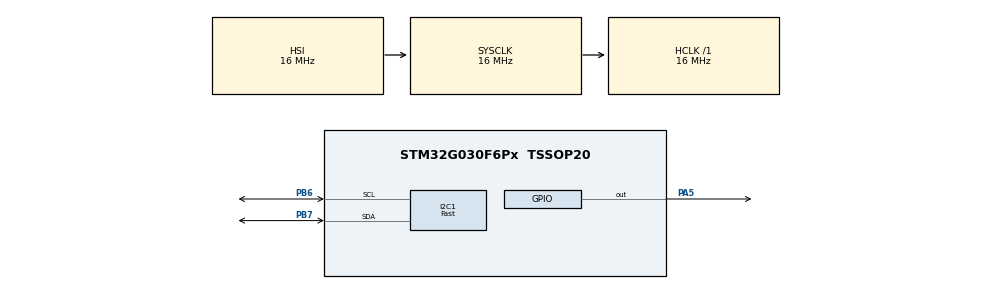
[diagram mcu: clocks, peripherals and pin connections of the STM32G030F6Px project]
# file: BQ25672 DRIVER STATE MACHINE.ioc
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Dma.I2C1_RX.0.Direction=DMA_PERIPH_TO_MEMORY
Dma.I2C1_RX.0.EventEnable=DISABLE
Dma.I2C1_RX.0.Instance=DMA1_Channel1
Dma.I2C1_RX.0.MemDataAlignment=DMA_MDATAALIGN_BYTE
Dma.I2C1_RX.0.MemInc=DMA_MINC_ENABLE
Dma.I2C1_RX.0.Mode=DMA_NORMAL
Dma.I2C1_RX.0.PeriphDataAlignment=DMA_PDATAALIGN_BYTE
Dma.I2C1_RX.0.PeriphInc=DMA_PINC_DISABLE
Dma.I2C1_RX.0.Polarity=HAL_DMAMUX_REQ_GEN_RISING
Dma.I2C1_RX.0.Priority=DMA_PRIORITY_LOW
Dma.I2C1_RX.0.RequestNumber=1
Dma.I2C1_RX.0.SignalID=NONE
Dma.I2C1_RX.0.SyncEnable=DISABLE
Dma.I2C1_RX.0.SyncPolarity=HAL_DMAMUX_SYNC_NO_EVENT
Dma.I2C1_RX.0.SyncRequestNumber=1
Dma.I2C1_RX.0.SyncSignalID=NONE
Dma.I2C1_TX.1.Direction=DMA_MEMORY_TO_PERIPH
Dma.I2C1_TX.1.EventEnable=DISABLE
Dma.I2C1_TX.1.Instance=DMA1_Channel2
Dma.I2C1_TX.1.MemDataAlignment=DMA_MDATAALIGN_BYTE
Dma.I2C1_TX.1.MemInc=DMA_MINC_ENABLE
Dma.I2C1_TX.1.Mode=DMA_NORMAL
Dma.I2C1_TX.1.PeriphDataAlignment=DMA_PDATAALIGN_BYTE
Dma.I2C1_TX.1.PeriphInc=DMA_PINC_DISABLE
Dma.I2C1_TX.1.Polarity=HAL_DMAMUX_REQ_GEN_RISING
Dma.I2C1_TX.1.Priority=DMA_PRIORITY_LOW
Dma.I2C1_TX.1.RequestNumber=1
Dma.I2C1_TX.1.SignalID=NONE
Dma.I2C1_TX.1.SyncEnable=DISABLE
Dma.I2C1_TX.1.SyncPolarity=HAL_DMAMUX_SYNC_NO_EVENT
Dma.I2C1_TX.1.SyncRequestNumber=1
Dma.I2C1_TX.1.SyncSignalID=NONE
Dma.Request0=I2C1_RX
Dma.Request1=I2C1_TX
I2C1.I2C_Speed_Mode=I2C_Fast
I2C1.Timing=0x00300617
Mcu.Family=STM32G0
Mcu.Name=STM32G030F6Px
Mcu.Package=TSSOP20
NVIC.DMA1_Channel1_IRQn=true\:0\:0\:false\:false\:true\:false\:true\:true
NVIC.DMA1_Channel2_3_IRQn=true\:0\:0\:false\:false\:true\:false\:true\:true
NVIC.TIM3_IRQn=true\:0\:0\:false\:false\:true\:true\:true\:true
PA14-BOOT0__PA15.StandardMode=true
PA5.Signal=GPIO_Output
PB0__PB1__PB2__PA8.StandardMode=true
PB3__PB4__PB5__PB6.StandardMode=true
PB6.Mode=I2C
PB6.Signal=I2C1_SCL
PB7.Mode=I2C
PB7.Signal=I2C1_SDA
PB7__PB8.StandardMode=true
PC14-OSC32_IN\ (PC14)__PB9.StandardMode=true
ProjectManager.HeapSize=0x200
ProjectManager.StackSize=0x400
ProjectManager.TargetToolchain=STM32CubeIDE
RCC.AHBFreq_Value=16000000
RCC.CortexFreq_Value=16000000
RCC.EXTERNAL_CLOCK_VALUE=12288000
RCC.HCLKFreq_Value=16000000
RCC.HSE_VALUE=8000000
RCC.HSI_VALUE=16000000
RCC.LSE_VALUE=32768
RCC.SYSCLKFreq_VALUE=16000000
RCC.VCOOutputFreq_Value=128000000
TIM3.AutoReloadPreload=TIM_AUTORELOAD_PRELOAD_ENABLE
TIM3.Period=99
TIM3.Prescaler=15999
VP_RTC_VS_RTC_Activate.Mode=RTC_Enabled
VP_TIM3_VS_ClockSourceINT.Mode=Internal
VP_TIM3_VS_ClockSourceITR.Mode=TriggerSource_ITR0
board=custom

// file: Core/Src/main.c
/* USER CODE BEGIN Header */
/**
  ******************************************************************************
  * @file           : main.c
  * @brief          : Main program body
  ******************************************************************************
  * @attention
  *
  * Copyright (c) 2025 STMicroelectronics.
  * All rights reserved.
  *
  * This software is licensed under terms that can be found in the LICENSE file
  * in the root directory of this software component.
  * If no LICENSE file comes with this software, it is provided AS-IS.
  *
  ******************************************************************************
  */
/* USER CODE END Header */
#include "main.h"

I2C_HandleTypeDef hi2c1;
DMA_HandleTypeDef hdma_i2c1_rx;
DMA_HandleTypeDef hdma_i2c1_tx;

RTC_HandleTypeDef hrtc;

TIM_HandleTypeDef htim3;

/* USER CODE BEGIN PV */
volatile uint8_t i2c_tx_complete = 0;
volatile uint8_t i2c_rx_complete = 0;
volatile uint8_t i2c_error = 0;
bq25672_config_t bq_config;
bq25672_status_t status;
volatile bool update_state_machine = false;
/* USER CODE END PV */

void SystemClock_Config(void);
static void MX_GPIO_Init(void);
static void MX_DMA_Init(void);
static void MX_I2C1_Init(void);
static void MX_RTC_Init(void);
static void MX_TIM3_Init(void);

int main(void)
{

  /* MCU Configuration--------------------------------------------------------*/

  /* Reset of all peripherals, Initializes the Flash interface and the Systick. */
  HAL_Init();

  /* Configure the system clock */
  SystemClock_Config();

  /* Initialize all configured peripherals */
  MX_GPIO_Init();
  MX_DMA_Init();
  MX_I2C1_Init();
  MX_RTC_Init();
  MX_TIM3_Init();
  /* USER CODE BEGIN 2 */

  // BQ25672 init with default configuration
//  if (bq25672_init(&hi2c1, NULL) != BQ25672_OK)
//      Error_Handler();

  // BQ25672 init with my max_eff_cfg configuration
	if (bq25672_init(&hi2c1, &BQ25672_MAX_EFFICIENCY_CONFIG) != BQ25672_OK)
		Error_Handler();

	/* Initialize BQ25672 state machine */
	status = bq25672_sm_init(&hi2c1, &bq_config);
	if (status != BQ25672_OK)
	    Error_Handler();

	HAL_TIM_Base_Start_IT(&htim3);
  /* USER CODE END 2 */

  /* Infinite loop */
  while (1)
  {
	  if (update_state_machine)
	  {
	        update_state_machine = false;
	        status = bq25672_sm_update(&hi2c1);
	        if (status != BQ25672_OK)
	          Error_Handler();
	        /* Sync I2C status with state machine */
	        if (i2c_error)
	          Error_Handler(); /* Handle I2C errors */

	        i2c_tx_complete = 0;
	        i2c_rx_complete = 0;
	        i2c_error = 0;
	  }
  }
}

void SystemClock_Config(void)
{
  RCC_OscInitTypeDef RCC_OscInitStruct = {0};
  RCC_ClkInitTypeDef RCC_ClkInitStruct = {0};

  /** Configure the main internal regulator output voltage
  */
  HAL_PWREx_ControlVoltageScaling(PWR_REGULATOR_VOLTAGE_SCALE1);

  /** Initializes the RCC Oscillators according to the specified parameters
  * in the RCC_OscInitTypeDef structure.
  */
  RCC_OscInitStruct.OscillatorType = RCC_OSCILLATORTYPE_HSI|RCC_OSCILLATORTYPE_LSI;
  RCC_OscInitStruct.HSIState = RCC_HSI_ON;
  RCC_OscInitStruct.HSIDiv = RCC_HSI_DIV1;
  RCC_OscInitStruct.HSICalibrationValue = RCC_HSICALIBRATION_DEFAULT;
  RCC_OscInitStruct.LSIState = RCC_LSI_ON;
  RCC_OscInitStruct.PLL.PLLState = RCC_PLL_NONE;
  if (HAL_RCC_OscConfig(&RCC_OscInitStruct) != HAL_OK)
  {
    Error_Handler();
  }

  /** Initializes the CPU, AHB and APB buses clocks
  */
  RCC_ClkInitStruct.ClockType = RCC_CLOCKTYPE_HCLK|RCC_CLOCKTYPE_SYSCLK
                              |RCC_CLOCKTYPE_PCLK1;
  RCC_ClkInitStruct.SYSCLKSource = RCC_SYSCLKSOURCE_HSI;
  RCC_ClkInitStruct.AHBCLKDivider = RCC_SYSCLK_DIV1;
  RCC_ClkInitStruct.APB1CLKDivider = RCC_HCLK_DIV1;

  if (HAL_RCC_ClockConfig(&RCC_ClkInitStruct, FLASH_LATENCY_0) != HAL_OK)
  {
    Error_Handler();
  }
}

static void MX_I2C1_Init(void)
{

  hi2c1.Instance = I2C1;
  hi2c1.Init.Timing = 0x00300617;
  hi2c1.Init.OwnAddress1 = 0;
  hi2c1.Init.AddressingMode = I2C_ADDRESSINGMODE_7BIT;
  hi2c1.Init.DualAddressMode = I2C_DUALADDRESS_DISABLE;
  hi2c1.Init.OwnAddress2 = 0;
  hi2c1.Init.OwnAddress2Masks = I2C_OA2_NOMASK;
  hi2c1.Init.GeneralCallMode = I2C_GENERALCALL_DISABLE;
  hi2c1.Init.NoStretchMode = I2C_NOSTRETCH_DISABLE;
  if (HAL_I2C_Init(&hi2c1) != HAL_OK)
  {
    Error_Handler();
  }

  /** Configure Analogue filter
  */
  if (HAL_I2CEx_ConfigAnalogFilter(&hi2c1, I2C_ANALOGFILTER_ENABLE) != HAL_OK)
  {
    Error_Handler();
  }

  /** Configure Digital filter
  */
  if (HAL_I2CEx_ConfigDigitalFilter(&hi2c1, 0) != HAL_OK)
  {
    Error_Handler();
  }

}

static void MX_RTC_Init(void)
{

  /** Initialize RTC Only
  */
  hrtc.Instance = RTC;
  hrtc.Init.HourFormat = RTC_HOURFORMAT_24;
  hrtc.Init.AsynchPrediv = 127;
  hrtc.Init.SynchPrediv = 255;
  hrtc.Init.OutPut = RTC_OUTPUT_DISABLE;
  hrtc.Init.OutPutRemap = RTC_OUTPUT_REMAP_NONE;
  hrtc.Init.OutPutPolarity = RTC_OUTPUT_POLARITY_HIGH;
  hrtc.Init.OutPutType = RTC_OUTPUT_TYPE_OPENDRAIN;
  hrtc.Init.OutPutPullUp = RTC_OUTPUT_PULLUP_NONE;
  if (HAL_RTC_Init(&hrtc) != HAL_OK)
  {
    Error_Handler();
  }

}

static void MX_TIM3_Init(void)
{

  TIM_ClockConfigTypeDef sClockSourceConfig = {0};
  TIM_SlaveConfigTypeDef sSlaveConfig = {0};
  TIM_MasterConfigTypeDef sMasterConfig = {0};

  htim3.Instance = TIM3;
  htim3.Init.Prescaler = 15999;
  htim3.Init.CounterMode = TIM_COUNTERMODE_UP;
  htim3.Init.Period = 99;
  htim3.Init.ClockDivision = TIM_CLOCKDIVISION_DIV1;
  htim3.Init.AutoReloadPreload = TIM_AUTORELOAD_PRELOAD_ENABLE;
  if (HAL_TIM_Base_Init(&htim3) != HAL_OK)
  {
    Error_Handler();
  }
  sClockSourceConfig.ClockSource = TIM_CLOCKSOURCE_INTERNAL;
  if (HAL_TIM_ConfigClockSource(&htim3, &sClockSourceConfig) != HAL_OK)
  {
    Error_Handler();
  }
  sSlaveConfig.SlaveMode = TIM_SLAVEMODE_DISABLE;
  sSlaveConfig.InputTrigger = TIM_TS_ITR0;
  if (HAL_TIM_SlaveConfigSynchro(&htim3, &sSlaveConfig) != HAL_OK)
  {
    Error_Handler();
  }
  sMasterConfig.MasterOutputTrigger = TIM_TRGO_RESET;
  sMasterConfig.MasterSlaveMode = TIM_MASTERSLAVEMODE_DISABLE;
  if (HAL_TIMEx_MasterConfigSynchronization(&htim3, &sMasterConfig) != HAL_OK)
  {
    Error_Handler();
  }

}

static void MX_DMA_Init(void)
{

  /* DMA controller clock enable */
  __HAL_RCC_DMA1_CLK_ENABLE();

  /* DMA interrupt init */
  /* DMA1_Channel1_IRQn interrupt configuration */
  HAL_NVIC_SetPriority(DMA1_Channel1_IRQn, 0, 0);
  HAL_NVIC_EnableIRQ(DMA1_Channel1_IRQn);
  /* DMA1_Channel2_3_IRQn interrupt configuration */
  HAL_NVIC_SetPriority(DMA1_Channel2_3_IRQn, 0, 0);
  HAL_NVIC_EnableIRQ(DMA1_Channel2_3_IRQn);

}

static void MX_GPIO_Init(void)
{
  GPIO_InitTypeDef GPIO_InitStruct = {0};

  /* GPIO Ports Clock Enable */
  __HAL_RCC_GPIOB_CLK_ENABLE();
  __HAL_RCC_GPIOA_CLK_ENABLE();

  /*Configure GPIO pin Output Level */
  HAL_GPIO_WritePin(GPIOA, GPIO_PIN_5, GPIO_PIN_RESET);

  /*Configure GPIO pin : PA5 */
  GPIO_InitStruct.Pin = GPIO_PIN_5;
  GPIO_InitStruct.Mode = GPIO_MODE_OUTPUT_PP;
  GPIO_InitStruct.Pull = GPIO_NOPULL;
  GPIO_InitStruct.Speed = GPIO_SPEED_FREQ_LOW;
  HAL_GPIO_Init(GPIOA, &GPIO_InitStruct);

}

void Error_Handler(void)
{
  __disable_irq();
  while (1)
  {
  }
}
